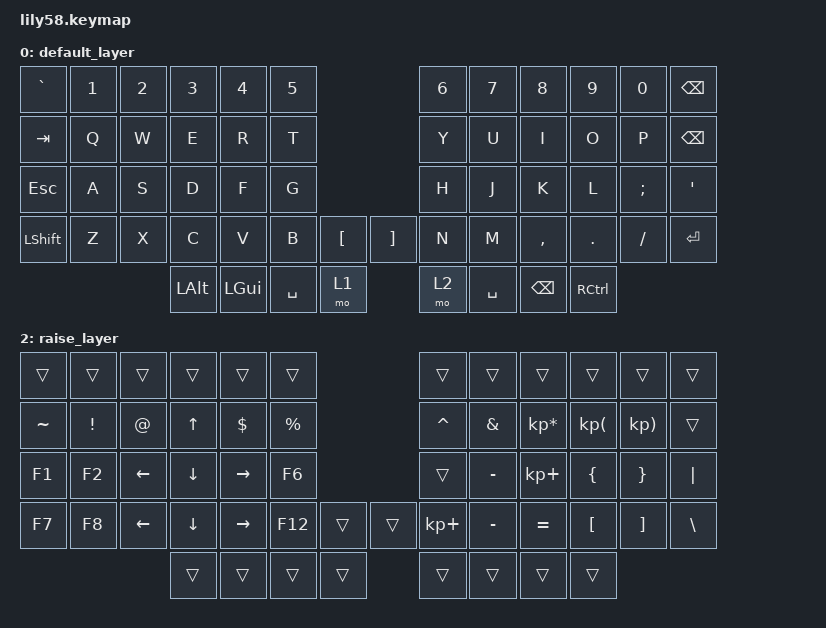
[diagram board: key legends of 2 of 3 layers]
/*
 * Copyright (c) 2020 The ZMK Contributors
 *
 * SPDX-License-Identifier: MIT
 */

#include <behaviors.dtsi>
#include <dt-bindings/zmk/keys.h>
#include <dt-bindings/zmk/bt.h>
#include <dt-bindings/zmk/ext_power.h>

/ {
	keymap {
		compatible = "zmk,keymap";

		default_layer {
// ------------------------------------------------------------------------------------------------------------
// |   `    |  1  |  2  |  3   |  4   |  5    |                     |  6   |  7    |  8    |  9   |   0   | BSPC  |
// |  TAB   |  Q  |  W  |  E   |  R   |  T    |                     |  Y   |  U    |  I    |  O   |   P   | BSPC  |
// |  ESC   |  A  |  S  |  D   |  F   |  G    |                     |  H   |  J    |  K    |  L   |   ;   |   '   |
// |  SHIFT |  Z  |  X  |  C   |  V   |  B    |   "["  |  |  "]"    |  N   |  M    |  ,    |  .   |   /   | ENTER |
//                      | ALT  | ALT  | LOWER |  GUI   |  | SPACE   | RAISE| RCTRL | GUI   |
// LCTRL
			bindings = <
&kp GRAVE	&kp N1	&kp N2   &kp N3   &kp N4   &kp N5              				    &kp N6 		&kp N7   &kp N8	&kp N9		&kp N0   	&kp BSPC
&kp TAB		&kp Q	&kp W    &kp E    &kp R    &kp T               				    &kp Y  		&kp U    &kp I	&kp O		&kp P   	&kp BSPC
&kp ESC		&kp A	&kp S    &kp D    &kp F    &kp G               				    &kp H  		&kp J    &kp K	&kp L		&kp SEMI	&kp SQT
&kp LSHFT	&kp Z	&kp X    &kp C    &kp V    &kp B     &kp LBKT		&kp RBKT	&kp N		&kp M	 &kp COMMA	&kp DOT		&kp FSLH 	&kp RET
							 &kp LALT &kp LGUI &kp SPACE &mo 1      			&mo 2  	&kp SPACE	&kp BSPC &kp RCTRL 
			>;
			sensor-bindings = <&inc_dec_kp C_VOL_UP C_VOL_DN &inc_dec_kp PG_UP PG_DN>;
		};

		lower_layer {
// ------------------------------------------------------------------------------------------------------------
// | BTCLR | BT1 | BT2  |  BT3   |  BT4   |  BT5    |                   |      |       |       |      |       |       |
// |  F1   |  F2 |  F3  |  F4    |  F5    |  F6     |                   |  F7  |  7    |  8    |  9   |  F11  |       |
// |   `   |  !  |  h1  |  h2    | Bullet | Numlist |                   |  ^   |  4    |  5    |  6   |   )   |   ~   |
// |       |     |      | screen | screen |         |        |  |       |      |  1    |  2    |  3   |   }   |  "|"  |
//                      |        |        |         |        |  |       |   0  |   .   |       |
			bindings = <
&bt BT_CLR &bt BT_SEL 0     &bt BT_SEL 1      &bt BT_SEL 2  &bt BT_SEL 3 	&bt BT_SEL 4                    		  &trans    &trans    &trans          &trans    &trans    &trans
&kp F1     &kp F2           &kp F3            &kp F4        &kp F5       	&kp F6                          		  &kp F7    &kp N7    &kp N8          &kp N9   &kp F11   &kp F12
&kp GRAVE  &kp EXCL         &kp LG(LA(N1))     &kp LG(LA(N2)) &kp LG(LS(N8))	&kp LG(LS(N7))                     		  &kp CARET &kp N4    &kp N5          &kp N6   &kp RPAR  &kp TILDE
&trans     &ext_power EP_ON  &trans  &kp LG(LC(LS(N4)))&kp LG(LS(N4))     	&trans    		&trans        	&trans    &trans    &kp N1    &kp N2          &kp N3   &kp RBRC  &kp PIPE
                            				  &trans        &trans      	&trans   		&trans    		&trans    &kp N0    &kp DOT   &trans
			>;

			sensor-bindings = <&inc_dec_kp C_VOL_UP C_VOL_DN &inc_dec_kp PG_UP PG_DN>;
		};

		raise_layer {
// ------------------------------------------------------------------------------------------------------------
// |       |     |       |       |        |      |                   |      |       |       |      |       |       |
// |   ~   |  !  |  @    |  up   |  $     |  %   |                   |  ^   |   &   |   *   |  (   |   )   |       |
// |   F1  |  F2 |  left |  down |  right |  F6  |                   |      |   -   |   +   |  {   |   }   |  "|"  |
// |   F7  |  F8 |  left |  down |  right |  F12 |        |  |       |  +   |   -   |   =   |  [   |   ]   |   \   |
//                       |       |        |      |        |  |       |      |       |       |
			bindings = <
&trans    &trans   &trans   &trans   &trans    &trans                       &trans		&trans    	&trans       	&trans   	&trans		&trans
&kp TILDE &kp EXCL &kp AT   &kp UP   &kp DLLR  &kp PRCNT                    &kp CARET	&kp AMPS    &kp KP_MULTIPLY	&kp KP_LPAR	&kp KP_RPAR	&trans    
&kp F1    &kp F2   &kp LEFT &kp DOWN &kp RIGHT &kp F6                       &trans		&kp MINUS 	&kp KP_PLUS  	&kp LBRC   	&kp RBRC 	&kp PIPE
&kp F7    &kp F8   &kp LEFT &kp DOWN &kp RIGHT &kp F12   &trans   &trans    &kp KP_PLUS	&kp MINUS 	&kp EQUAL    	&kp LBKT 	&kp RBKT  	&kp BSLH
                            &trans   &trans    &trans    &trans   &trans    &trans      &trans    &trans
			>;

			sensor-bindings = <&inc_dec_kp C_VOL_UP C_VOL_DN &inc_dec_kp PG_UP PG_DN>;
		};
	};
};
